AUTOSAR XML (schema 00049)
package /RB/PT/PCT_DcmSample_Requirer/SwComponentTypes
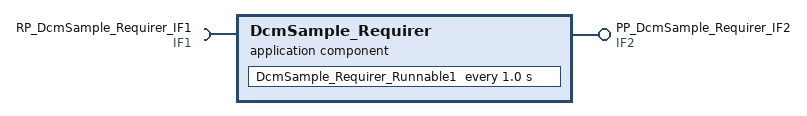
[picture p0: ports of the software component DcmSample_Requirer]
  application sw component type DcmSample_Requirer
    provide port PP_DcmSample_Requirer_IF2: provided-interface=IF2
    require port RP_DcmSample_Requirer_IF1: required-interface=IF1
    behavior IB_DcmSample_Requirer: data-type-mapping=[DTMS_DcmSample_Requirer, DTMS_DcmSample_Provider]
      timing event DcmSample_Requirer_Runnable1_TimingEvent: start-on-event=DcmSample_Requirer_Runnable1, period=1.0
      runnable DcmSample_Requirer_Runnable1: reentrancy-level=NON-REENTRANT, symbol=DcmSample_Requirer_Runnable1_fnc
        data-receive-point-by-values:
          access DcmSample_Provider_Runnable1_RP_IF1: accessed-variable=RP_DcmSample_Requirer_IF1.IF1_var1
        data-send-points:
          access DcmSample_Provider_Runnable1_PP_IF2: accessed-variable=PP_DcmSample_Requirer_IF2.IF2_var1
package /RB/PT/PCT_DcmSample_Requirer/PortInterfaces
  sender receiver interface IF2
    data IF2_var1: sw-calibration-access=READ-ONLY, type=uint8
package /RB/PT/PCT_DcmSample_Requirer/ApplicationDataTypes
  app type uint8: category=VALUE, sw-calibration-access=READ-WRITE, range phys 0..255 RBPtCel_NoUnit
package /RB/PT/PCT_DcmSample_Requirer/DataTypeMappingSets
  data type mapping set DTMS_DcmSample_Requirer: data-type-map{application-data-type=uint8, implementation-data-type=uint8}
